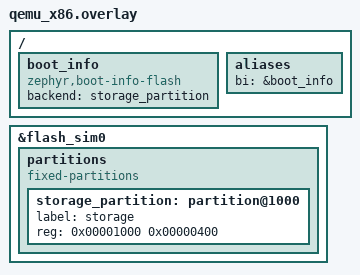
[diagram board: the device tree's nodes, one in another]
/*
 * Copyright (c) 2023 Laczen
 * SPDX-License-Identifier: Apache-2.0
 */

/delete-node/ &storage_partition;

&flash_sim0 {

	partitions {
		compatible = "fixed-partitions";
		#address-cells = <1>;
		#size-cells = <1>;

		storage_partition: partition@1000 {
			label = "storage";
			reg = <0x00001000 0x00000400>;
		};
	};
};

/ {
        boot_info: boot_info {
                compatible = "zephyr,boot-info-flash";
                backend = <&storage_partition>;
        };

        aliases {
                bi = &boot_info;
        };

};
